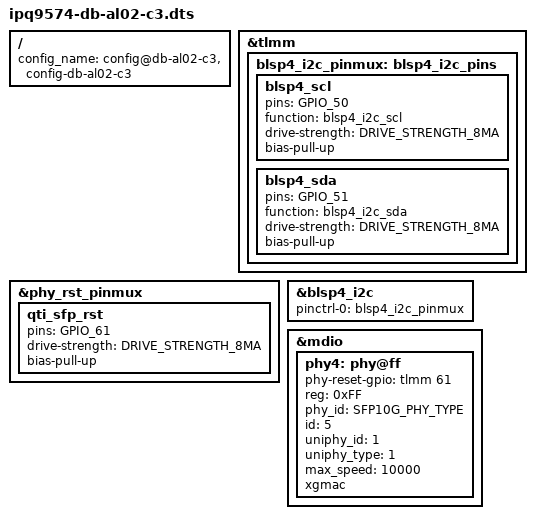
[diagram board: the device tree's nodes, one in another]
// SPDX-License-Identifier: GPL-2.0-only
/*
* Copyright (c) 2023, Qualcomm Innovation Center, Inc. All rights reserved.
*/

#include "ipq9574-db-al02-c1.dts"

/ {
	config_name = "config@db-al02-c3", "config-db-al02-c3";

};

&tlmm {
	blsp4_i2c_pinmux: blsp4_i2c_pins {
		blsp4_scl {
			pins = "GPIO_50";
			function = "blsp4_i2c_scl";
			drive-strength = <DRIVE_STRENGTH_8MA>;
			bias-pull-up;
		};

		blsp4_sda {
			pins = "GPIO_51";
			function = "blsp4_i2c_sda";
			drive-strength = <DRIVE_STRENGTH_8MA>;
			bias-pull-up;
		};
	};
};

&phy_rst_pinmux {
	/delete-node/ qti_8081_rst;

	qti_sfp_rst {
		pins = "GPIO_61";
		drive-strength = <DRIVE_STRENGTH_8MA>;
		bias-pull-up;
	};
};

&blsp4_i2c {
	pinctrl-names = "default";
	pinctrl-0 = <&blsp4_i2c_pinmux>;
	status = "okay";
};

/delete-node/ &phy4;

&mdio {
	phy4: phy@ff {
		phy-reset-gpio = <&tlmm 61 0>;
		reg = <0xFF>;
		phy_id = <SFP10G_PHY_TYPE>;
		id = <5>;
		uniphy_id = <1>;
		uniphy_type = <1>;
		max_speed = <10000>;
		xgmac;
	};
};
